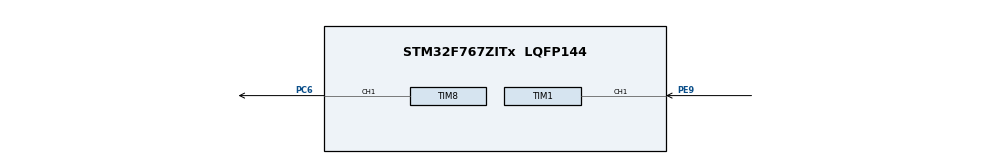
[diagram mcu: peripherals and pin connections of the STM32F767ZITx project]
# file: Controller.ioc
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Mcu.Family=STM32F7
Mcu.Name=STM32F767ZITx
Mcu.Package=LQFP144
NVIC.PriorityGroup=NVIC_PRIORITYGROUP_4
NVIC.TIM1_CC_IRQn=true\:0\:0\:false\:false\:true\:true\:true
NVIC.TIM1_UP_TIM10_IRQn=true\:0\:0\:false\:false\:true\:true\:true
PC6.Signal=S_TIM8_CH1
PE9.Signal=S_TIM1_CH1
ProjectManager.HeapSize=0x200
ProjectManager.StackSize=0x400
ProjectManager.TargetToolchain=TrueSTUDIO
RCC.APB1Freq_Value=16000000
RCC.APB1TimFreq_Value=16000000
RCC.APB2Freq_Value=16000000
RCC.APB2TimFreq_Value=16000000
RCC.HSE_VALUE=25000000
RCC.HSICalibrationValue=18
RCC.HSI_VALUE=16000000
RCC.LSE_VALUE=32768
RCC.USBFreq_Value=96000000
RCC.VCOOutputFreq_Value=192000000
SH.S_TIM1_CH1.0=TIM1_CH1,Input_Capture1_from_TI1
SH.S_TIM8_CH1.0=TIM8_CH1,PWM Generation1 CH1
TIM1.AutoReloadPreload=TIM_AUTORELOAD_PRELOAD_DISABLE
TIM1.Channel-Input_Capture1_from_TI1=TIM_CHANNEL_1
TIM1.ClockDivision=TIM_CLOCKDIVISION_DIV1
TIM1.ICPolarity_CH1=TIM_INPUTCHANNELPOLARITY_BOTHEDGE
TIM1.Period=0xffff
TIM1.Prescaler=4
TIM8.Channel-PWM\ Generation1\ CH1=TIM_CHANNEL_1
TIM8.Period=63999
TIM8.Prescaler=4
TIM8.Pulse-PWM\ Generation1\ CH1=31999
board=custom

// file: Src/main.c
/* USER CODE BEGIN Header */
/**
  ******************************************************************************
  * @file           : main.c
  * @brief          : Main program body
  ******************************************************************************
  * @attention
  *
  * <h2><center>&copy; Copyright (c) 2020 STMicroelectronics.
  * All rights reserved.</center></h2>
  *
  * This software component is licensed by ST under BSD 3-Clause license,
  * the "License"; You may not use this file except in compliance with the
  * License. You may obtain a copy of the License at:
  *                        opensource.org/licenses/BSD-3-Clause
  *
  ******************************************************************************
  */
/* USER CODE END Header */

#include "main.h"

/* USER CODE BEGIN Includes */
#include <stdio.h>
/* USER CODE END Includes */

/* USER CODE BEGIN PD */
#define FREQ_COUNT 3.2e6
/* USER CODE END PD */

TIM_HandleTypeDef htim1;
TIM_HandleTypeDef htim8;

/* USER CODE BEGIN PV */
/* Captured Value */
volatile uint16_t    uwIC2Value[6];
volatile uint16_t    uwIC2Value2[6];
volatile uint16_t    uwIC2Value3[6];
//volatile uint16_t    first_cycle[6];
//volatile uint16_t    second_cycle[6];
//volatile uint16_t    full_cycle[6];
volatile uint8_t state[6];

/* Duty Cycle Value */
volatile uint32_t            uwDutyCycle = 0;
/* Frequency Value */
volatile uint32_t            uwFrequency = 0;
/* USER CODE END PV */

void SystemClock_Config(void);
static void MX_GPIO_Init(void);
static void MX_TIM1_Init(void);
static void MX_TIM8_Init(void);

int main(void)
{

  /* MCU Configuration--------------------------------------------------------*/

  /* Reset of all peripherals, Initializes the Flash interface and the Systick. */
  HAL_Init();

  /* Configure the system clock */
  SystemClock_Config();

  /* Initialize all configured peripherals */
  MX_GPIO_Init();
  MX_TIM1_Init();
  MX_TIM8_Init();
  /* USER CODE BEGIN 2 */
  if(HAL_TIM_IC_Start_IT(&htim1,TIM_CHANNEL_1) != HAL_OK){
	  Error_Handler();
  }
  if(HAL_TIM_PWM_Start(&htim8,TIM_CHANNEL_1)!= HAL_OK){
	  Error_Handler();
  }
  /* USER CODE END 2 */

  /* Infinite loop */
  while (1)
  {

  }
}

void SystemClock_Config(void)
{
  RCC_OscInitTypeDef RCC_OscInitStruct = {0};
  RCC_ClkInitTypeDef RCC_ClkInitStruct = {0};

  /** Configure the main internal regulator output voltage
  */
  __HAL_RCC_PWR_CLK_ENABLE();
  __HAL_PWR_VOLTAGESCALING_CONFIG(PWR_REGULATOR_VOLTAGE_SCALE3);
  /** Initializes the CPU, AHB and APB busses clocks
  */
  RCC_OscInitStruct.OscillatorType = RCC_OSCILLATORTYPE_HSI;
  RCC_OscInitStruct.HSIState = RCC_HSI_ON;
  RCC_OscInitStruct.HSICalibrationValue = 18;
  RCC_OscInitStruct.PLL.PLLState = RCC_PLL_NONE;
  if (HAL_RCC_OscConfig(&RCC_OscInitStruct) != HAL_OK)
  {
    Error_Handler();
  }
  /** Initializes the CPU, AHB and APB busses clocks
  */
  RCC_ClkInitStruct.ClockType = RCC_CLOCKTYPE_HCLK|RCC_CLOCKTYPE_SYSCLK
                              |RCC_CLOCKTYPE_PCLK1|RCC_CLOCKTYPE_PCLK2;
  RCC_ClkInitStruct.SYSCLKSource = RCC_SYSCLKSOURCE_HSI;
  RCC_ClkInitStruct.AHBCLKDivider = RCC_SYSCLK_DIV1;
  RCC_ClkInitStruct.APB1CLKDivider = RCC_HCLK_DIV1;
  RCC_ClkInitStruct.APB2CLKDivider = RCC_HCLK_DIV1;

  if (HAL_RCC_ClockConfig(&RCC_ClkInitStruct, FLASH_LATENCY_0) != HAL_OK)
  {
    Error_Handler();
  }
}

static void MX_TIM1_Init(void)
{

  TIM_MasterConfigTypeDef sMasterConfig = {0};
  TIM_IC_InitTypeDef sConfigIC = {0};

  htim1.Instance = TIM1;
  htim1.Init.Prescaler = 4;
  htim1.Init.CounterMode = TIM_COUNTERMODE_UP;
  htim1.Init.Period = 0xffff;
  htim1.Init.ClockDivision = TIM_CLOCKDIVISION_DIV1;
  htim1.Init.RepetitionCounter = 0;
  htim1.Init.AutoReloadPreload = TIM_AUTORELOAD_PRELOAD_DISABLE;
  if (HAL_TIM_IC_Init(&htim1) != HAL_OK)
  {
    Error_Handler();
  }
  sMasterConfig.MasterOutputTrigger = TIM_TRGO_RESET;
  sMasterConfig.MasterOutputTrigger2 = TIM_TRGO2_RESET;
  sMasterConfig.MasterSlaveMode = TIM_MASTERSLAVEMODE_DISABLE;
  if (HAL_TIMEx_MasterConfigSynchronization(&htim1, &sMasterConfig) != HAL_OK)
  {
    Error_Handler();
  }
  sConfigIC.ICPolarity = TIM_INPUTCHANNELPOLARITY_BOTHEDGE;
  sConfigIC.ICSelection = TIM_ICSELECTION_DIRECTTI;
  sConfigIC.ICPrescaler = TIM_ICPSC_DIV1;
  sConfigIC.ICFilter = 0;
  if (HAL_TIM_IC_ConfigChannel(&htim1, &sConfigIC, TIM_CHANNEL_1) != HAL_OK)
  {
    Error_Handler();
  }

}

static void MX_TIM8_Init(void)
{

  TIM_MasterConfigTypeDef sMasterConfig = {0};
  TIM_OC_InitTypeDef sConfigOC = {0};
  TIM_BreakDeadTimeConfigTypeDef sBreakDeadTimeConfig = {0};

  htim8.Instance = TIM8;
  htim8.Init.Prescaler = 4;
  htim8.Init.CounterMode = TIM_COUNTERMODE_UP;
  htim8.Init.Period = 63999;
  htim8.Init.ClockDivision = TIM_CLOCKDIVISION_DIV1;
  htim8.Init.RepetitionCounter = 0;
  htim8.Init.AutoReloadPreload = TIM_AUTORELOAD_PRELOAD_DISABLE;
  if (HAL_TIM_PWM_Init(&htim8) != HAL_OK)
  {
    Error_Handler();
  }
  sMasterConfig.MasterOutputTrigger = TIM_TRGO_RESET;
  sMasterConfig.MasterOutputTrigger2 = TIM_TRGO2_RESET;
  sMasterConfig.MasterSlaveMode = TIM_MASTERSLAVEMODE_DISABLE;
  if (HAL_TIMEx_MasterConfigSynchronization(&htim8, &sMasterConfig) != HAL_OK)
  {
    Error_Handler();
  }
  sConfigOC.OCMode = TIM_OCMODE_PWM1;
  sConfigOC.Pulse = 31999;
  sConfigOC.OCPolarity = TIM_OCPOLARITY_HIGH;
  sConfigOC.OCNPolarity = TIM_OCNPOLARITY_HIGH;
  sConfigOC.OCFastMode = TIM_OCFAST_DISABLE;
  sConfigOC.OCIdleState = TIM_OCIDLESTATE_RESET;
  sConfigOC.OCNIdleState = TIM_OCNIDLESTATE_RESET;
  if (HAL_TIM_PWM_ConfigChannel(&htim8, &sConfigOC, TIM_CHANNEL_1) != HAL_OK)
  {
    Error_Handler();
  }
  sBreakDeadTimeConfig.OffStateRunMode = TIM_OSSR_DISABLE;
  sBreakDeadTimeConfig.OffStateIDLEMode = TIM_OSSI_DISABLE;
  sBreakDeadTimeConfig.LockLevel = TIM_LOCKLEVEL_OFF;
  sBreakDeadTimeConfig.DeadTime = 0;
  sBreakDeadTimeConfig.BreakState = TIM_BREAK_DISABLE;
  sBreakDeadTimeConfig.BreakPolarity = TIM_BREAKPOLARITY_HIGH;
  sBreakDeadTimeConfig.BreakFilter = 0;
  sBreakDeadTimeConfig.Break2State = TIM_BREAK2_DISABLE;
  sBreakDeadTimeConfig.Break2Polarity = TIM_BREAK2POLARITY_HIGH;
  sBreakDeadTimeConfig.Break2Filter = 0;
  sBreakDeadTimeConfig.AutomaticOutput = TIM_AUTOMATICOUTPUT_DISABLE;
  if (HAL_TIMEx_ConfigBreakDeadTime(&htim8, &sBreakDeadTimeConfig) != HAL_OK)
  {
    Error_Handler();
  }
  HAL_TIM_MspPostInit(&htim8);

}

static void MX_GPIO_Init(void)
{

  /* GPIO Ports Clock Enable */
  __HAL_RCC_GPIOE_CLK_ENABLE();
  __HAL_RCC_GPIOC_CLK_ENABLE();

}

/* USER CODE BEGIN 4 */

double linear_trasformation(double dc){
	return 1.666667*dc - 0.0666667;
}

double calc_dc(uint16_t t1,uint16_t t2,uint16_t t3){
	uint16_t second_cycle,first_cycle;
    if(t3 < t2){
    	second_cycle = (0xFFFF - t2) + t3;
    }else{
    	second_cycle = t3 - t2;
    }
    if(t2 < t1){
    	first_cycle = (0xFFFF - t1) + t2;
    }else{
    	first_cycle = t2 - t1;
    }
    //double freq = FREQ_COUNT/(double)(first_cycle+second_cycle);
    double dc =  ((double)first_cycle)/((double)(first_cycle+second_cycle));
    if(dc > 0.5){
    	dc =  1 - dc;
    }
    dc = linear_trasformation(dc);
    return dc;
}

void follow_pwm(TIM_HandleTypeDef *htim,size_t channel){
	switch(state[channel]){
		  case 0:
			    uwIC2Value[channel] = HAL_TIM_ReadCapturedValue(htim, channel);
			    state[channel] = 1;
			    break;
		  case 1:
			    uwIC2Value2[channel] = HAL_TIM_ReadCapturedValue(htim, channel);
			    state[channel] = 2;
			    break;
		  case 2:
			    uwIC2Value3[channel] = HAL_TIM_ReadCapturedValue(htim, channel);
			    uint16_t cycle_to_write = (uint16_t)htim8.Init.Period*calc_dc(uwIC2Value[channel],uwIC2Value2[channel],uwIC2Value3[channel]);
			    __HAL_TIM_SET_COMPARE(&htim8,TIM_CHANNEL_1,cycle_to_write);
			    state[channel] = 0;
			    break;
		  }

}

void HAL_TIM_IC_CaptureCallback(TIM_HandleTypeDef *htim)
{
  follow_pwm(htim,htim->Channel-1);
  /*if(htim->Channel == HAL_TIM_ACTIVE_CHANNEL_1){
	  uwIC2Value = HAL_TIM_ReadCapturedValue(htim, TIM_CHANNEL_2);
  }*/
}
/* USER CODE END 4 */

void Error_Handler(void)
{
}

/************************ (C) COPYRIGHT STMicroelectronics *****END OF FILE****/
